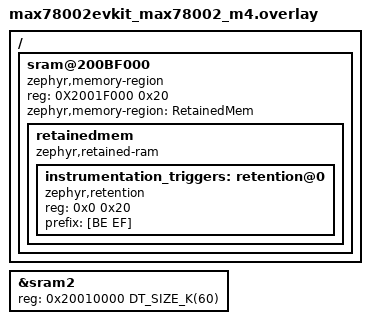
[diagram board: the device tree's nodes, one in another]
/ {
	sram@200BF000 {
		compatible = "zephyr,memory-region", "mmio-sram";
		reg = <0X2001F000 0x20>;
		zephyr,memory-region = "RetainedMem";
		status = "okay";

		retainedmem {
			compatible = "zephyr,retained-ram";
			status = "okay";
			#address-cells = <1>;
			#size-cells = <1>;

			instrumentation_triggers: retention@0 {
				compatible = "zephyr,retention";
				status = "okay";

				reg = <0x0 0x20>;

				prefix = [BE EF];
			};
		};
	};
};

&sram2 {
	reg = <0x20010000 DT_SIZE_K(60)>;
};
